# GD32G5x3 register map
File version: 1.0
CPU: CM33 r2p1, little endian, MPU, FPU, 4 interrupt priority bits
Registers are 32-bit, read-write, reset 0x0 unless marked. A register's access mark holds for its fields unless they carry their own. Offsets are from the block's base; [hi:lo] are bit positions.

## LPTIMER — Low power timer
Base 0x40009400
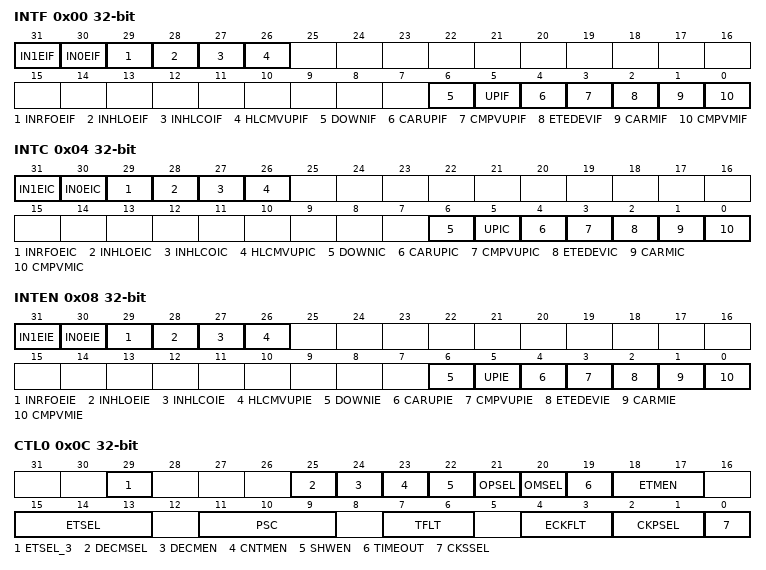
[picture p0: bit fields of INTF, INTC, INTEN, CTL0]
0x00 INTF ro — Interrupt flag register
  [31] IN1EIF — LPTIMER_IN1 error interrupt flag
  [30] IN0EIF — LPTIMER_IN0 error interrupt flag
  [29] INRFOEIF — The falling and rising edges of LPTIMER_IN0 and LPTIMER_IN1 overlap error interrupt flag
  [28] INHLOEIF — The high level of LPTIMER_IN0 and LPTIMER_IN1 overlap error interrupt flag
  [27] INHLCOIF — LPTIMER_INx(x=0,1) high level counter overflow interrupt flag
  [26] HLCMVUPIF — Input high level counter max value register update interrupt flag
  [6] DOWNIF — LPTIMER counter direction change up to down interrupt flag
  [5] UPIF — LPTIMER counter direction change down to up interrupt flag
  [4] CARUPIF — Counter auto reload register update interrupt flag
  [3] CMPVUPIF — Compare value register update interrupt flag
  [2] ETEDEVIF — External trigger edge event interrupt flag
  [1] CARMIF — Counter auto reload register match interrupt flag
  [0] CMPVMIF — Compare value register match interrupt flag
0x04 INTC wo — Interrupt flag clear register
  [31] IN1EIC — LPTIMER_IN1 error interrupt flag clear bit
  [30] IN0EIC — LPTIMER_IN0 error interrupt flag clear bit
  [29] INRFOEIC — The falling and rising edges of LPTIMER_IN0 and LPTIMER_IN1 overlap error interrupt flag clear bit
  [28] INHLOEIC — The high level of LPTIMER_IN0 and LPTIMER_IN1 overlap error interrupt flag clear bit
  [27] INHLCOIC — LPTIMER_INx(x=0, 1) high level counter overflow interrupt flag clear bit
  [26] HLCMVUPIC — Input high level counter max value register update interrupt flag clear bit
  [6] DOWNIC — LPTIMER counter direction change up to down interrupt flag clear bit
  [5] UPIC — LPTIMER counter direction change down to up interrupt flag clear bit
  [4] CARUPIC — Counter auto reload register update interrupt flag clear bit
  [3] CMPVUPIC — Compare value register update interrupt flag clear bit
  [2] ETEDEVIC — External trigger edge event interrupt flag clear bit
  [1] CARMIC — Counter auto reload register match interrupt flag clear bit
  [0] CMPVMIC — Compare value register match interrupt flag clear bit
0x08 INTEN — Interrupt enable register
  [31] IN1EIE — LPTIMER_IN1 error interrupt enable bit
  [30] IN0EIE — LPTIMER_IN0 error interrupt enable bit
  [29] INRFOEIE — The falling and rising edges of LPTIMER_IN0 and LPTIMER_IN1 overlap error interrupt enable bit
  [28] INHLOEIE — The high level of LPTIMER_IN0 and LPTIMER_IN1 overlap error interrupt enable bit
  [27] INHLCOIE — LPTIMER_INx(x=0,1) high level counter overflow interrupt enable bit
  [26] HLCMVUPIE — Input high level counter max value register update interrupt enable bit
  [6] DOWNIE — LPTIMER counter direction change up to down interrupt enable bit
  [5] UPIE — LPTIMER counter direction change down to up interrupt enable bit
  [4] CARUPIE — Counter auto reload register update interrupt enable bit
  [3] CMPVUPIE — Compare value register update interrupt enable bit
  [2] ETEDEVIE — External trigger edge event interrupt enable bit
  [1] CARMIE — Counter auto reload register match interrupt enable bit
  [0] CMPVMIE — Compare value register match interrupt enable bit
0x0C CTL0 — Control register 0
  [29] ETSEL_3 — External trigger select
  [25] DECMSEL — Decoder mode select
  [24] DECMEN — Decoder mode enabled
  [23] CNTMEN — Counter mode select
  [22] SHWEN — LPTIMER_CAR and LPTIMER_CMPV shadow registers enable
  [21] OPSEL — Output polarity select
  [20] OMSEL — Output Mode select
  [19] TIMEOUT — Timeout mode enable
  [18:17] ETMEN — External Trigger mode enable
  [15:13] ETSEL — External trigger select
  [11:9] PSC — Clock prescaler selection
  [7:6] TFLT — Trigger filter
  [4:3] ECKFLT — External clock filter
  [2:1] CKPSEL — Clock polarity select
  [0] CKSSEL — Clock source select
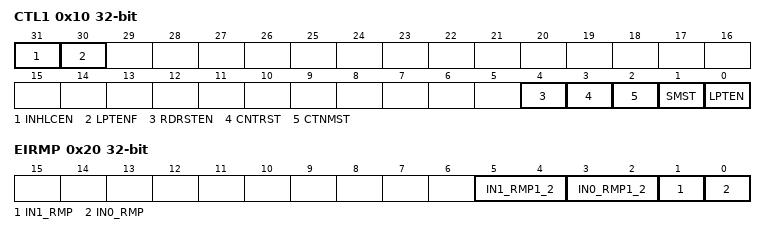
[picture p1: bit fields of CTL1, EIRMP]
0x10 CTL1 access per field — Control register 1
  [31] INHLCEN rw — LPTIMER external input high level counter enable
  [30] LPTENF ro — LPTIMER enabled from LPTIMER core flag
  [4] RDRSTEN rw — Read cause LPTIMER_CNT asynchronously reset enable
  [3] CNTRST rw — Counter (LPTIMER_CNT) synchronously reset
  [2] CTNMST rw — LPTIMER start for continuous counting mode
  [1] SMST rw — LPTIMER start for single counting mode
  [0] LPTEN rw — LPTIMER enable
0x14 CMPV — Compare value register
  [15:0] CMPVAL — Compare value
0x18 CAR reset 0x1 — Counter auto reload register
  [15:0] CARL — Counter auto reload value
0x1C CNT ro — Counter register
  [15:0] CNT — Counter value
0x20 EIRMP — External input remap register
  [5:4] IN1_RMP1_2 — LPTIMER input1 remap extension
  [3:2] IN0_RMP1_2 — LPTIMER input0 remap extension
  [1] IN1_RMP — External input1 remap
  [0] IN0_RMP — External input0 remap
0x24 INHLCMV — Input high level counter max value register
  [25:0] INHLCMVAL — Input high level counter max value
